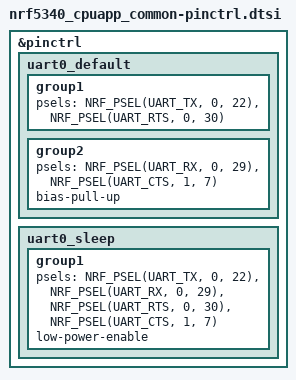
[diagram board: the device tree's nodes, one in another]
/*
 * Copyright (c) 2022 Nordic Semiconductor
 * SPDX-License-Identifier: Apache-2.0
 */

&pinctrl {
	/*i2c1_default: i2c1_default {
		group1 {
			psels = <NRF_PSEL(TWIM_SDA, 1, 2)>,
				<NRF_PSEL(TWIM_SCL, 1, 3)>;
		};
	};

	i2c1_sleep: i2c1_sleep {
		group1 {
			psels = <NRF_PSEL(TWIM_SDA, 1, 2)>,
				<NRF_PSEL(TWIM_SCL, 1, 3)>;
			low-power-enable;
		};
	};*/
	uart0_default: uart0_default {
		group1 {
			psels = <NRF_PSEL(UART_TX, 0, 22)>,   //orig: 20, pololu: 26
				<NRF_PSEL(UART_RTS, 0, 30)>;    //orig: 19, pololu: 27
		};
		group2 {
			psels = <NRF_PSEL(UART_RX, 0, 29)>,   //orig: 22, pololu: 6
				<NRF_PSEL(UART_CTS, 1, 7)>;   //orig: 21, pololu: 7
			bias-pull-up;
		};
		
	};

	uart0_sleep: uart0_sleep {
		group1 {
			psels = <NRF_PSEL(UART_TX, 0, 22)>,
				<NRF_PSEL(UART_RX, 0, 29)>,
				<NRF_PSEL(UART_RTS, 0, 30)>,
				<NRF_PSEL(UART_CTS, 1, 7)>;
			low-power-enable;
		};
	};
	/* should be good but not working through ob yet
	uart0_default: uart0_default {
		group1 {
			psels = <NRF_PSEL(UART_TX, 0, 29)>,   //orig: 20, pololu: 26
				<NRF_PSEL(UART_RTS, 0, 30)>;    //orig: 19, pololu: 27
		};
		group2 {
			psels = <NRF_PSEL(UART_RX, 0, 22)>,   //orig: 22, pololu: 6
				<NRF_PSEL(UART_CTS, 1, 7)>;   //orig: 21, pololu: 7
			bias-pull-up;
		};
		
	};

	uart0_sleep: uart0_sleep {
		group1 {
			psels = <NRF_PSEL(UART_TX, 0, 29)>,
				<NRF_PSEL(UART_RX, 0, 22)>,
				<NRF_PSEL(UART_RTS, 0, 30)>,
				<NRF_PSEL(UART_CTS, 1, 7)>;
			low-power-enable;
		};
	};*/

	/*pwm0_default: pwm0_default {
		group1 {
			psels = <NRF_PSEL(PWM_OUT0, 0, 28)>;
		};
	};

	pwm0_sleep: pwm0_sleep {
		group1 {
			psels = <NRF_PSEL(PWM_OUT0, 0, 28)>;
			low-power-enable;
		};
	};*/

	/*qspi_default: qspi_default {
		group1 {
			psels = <NRF_PSEL(QSPI_SCK, 0, 17)>,
				<NRF_PSEL(QSPI_IO0, 0, 13)>,
				<NRF_PSEL(QSPI_IO1, 0, 14)>,
				<NRF_PSEL(QSPI_IO2, 0, 15)>,
				<NRF_PSEL(QSPI_IO3, 0, 16)>,
				<NRF_PSEL(QSPI_CSN, 0, 18)>;
		};
	};

	qspi_sleep: qspi_sleep {
		group1 {
			psels = <NRF_PSEL(QSPI_SCK, 0, 17)>,
				<NRF_PSEL(QSPI_IO0, 0, 13)>,
				<NRF_PSEL(QSPI_IO1, 0, 14)>,
				<NRF_PSEL(QSPI_IO2, 0, 15)>,
				<NRF_PSEL(QSPI_IO3, 0, 16)>,
				<NRF_PSEL(QSPI_CSN, 0, 18)>;
			low-power-enable;
		};
	};*/

	/*uart1_default: uart1_default {
		group1 {
			psels = <NRF_PSEL(UART_TX, 1, 1)>;
		};
		group2 {
			psels = <NRF_PSEL(UART_RX, 1, 0)>;
			bias-pull-up;
		};
	};

	uart1_sleep: uart1_sleep {
		group1 {
			psels = <NRF_PSEL(UART_TX, 1, 1)>,
				<NRF_PSEL(UART_RX, 1, 0)>;
			low-power-enable;
		};
	};*/

	/*spi4_default: spi4_default {
		group1 {
			psels = <NRF_PSEL(SPIM_SCK, 1, 15)>,
				<NRF_PSEL(SPIM_MISO, 1, 14)>,
				<NRF_PSEL(SPIM_MOSI, 1, 13)>;
		};
	};

	spi4_sleep: spi4_sleep {
		group1 {
			psels = <NRF_PSEL(SPIM_SCK, 1, 15)>,
				<NRF_PSEL(SPIM_MISO, 1, 14)>,
				<NRF_PSEL(SPIM_MOSI, 1, 13)>;
			low-power-enable;
		};
	};*/

};
